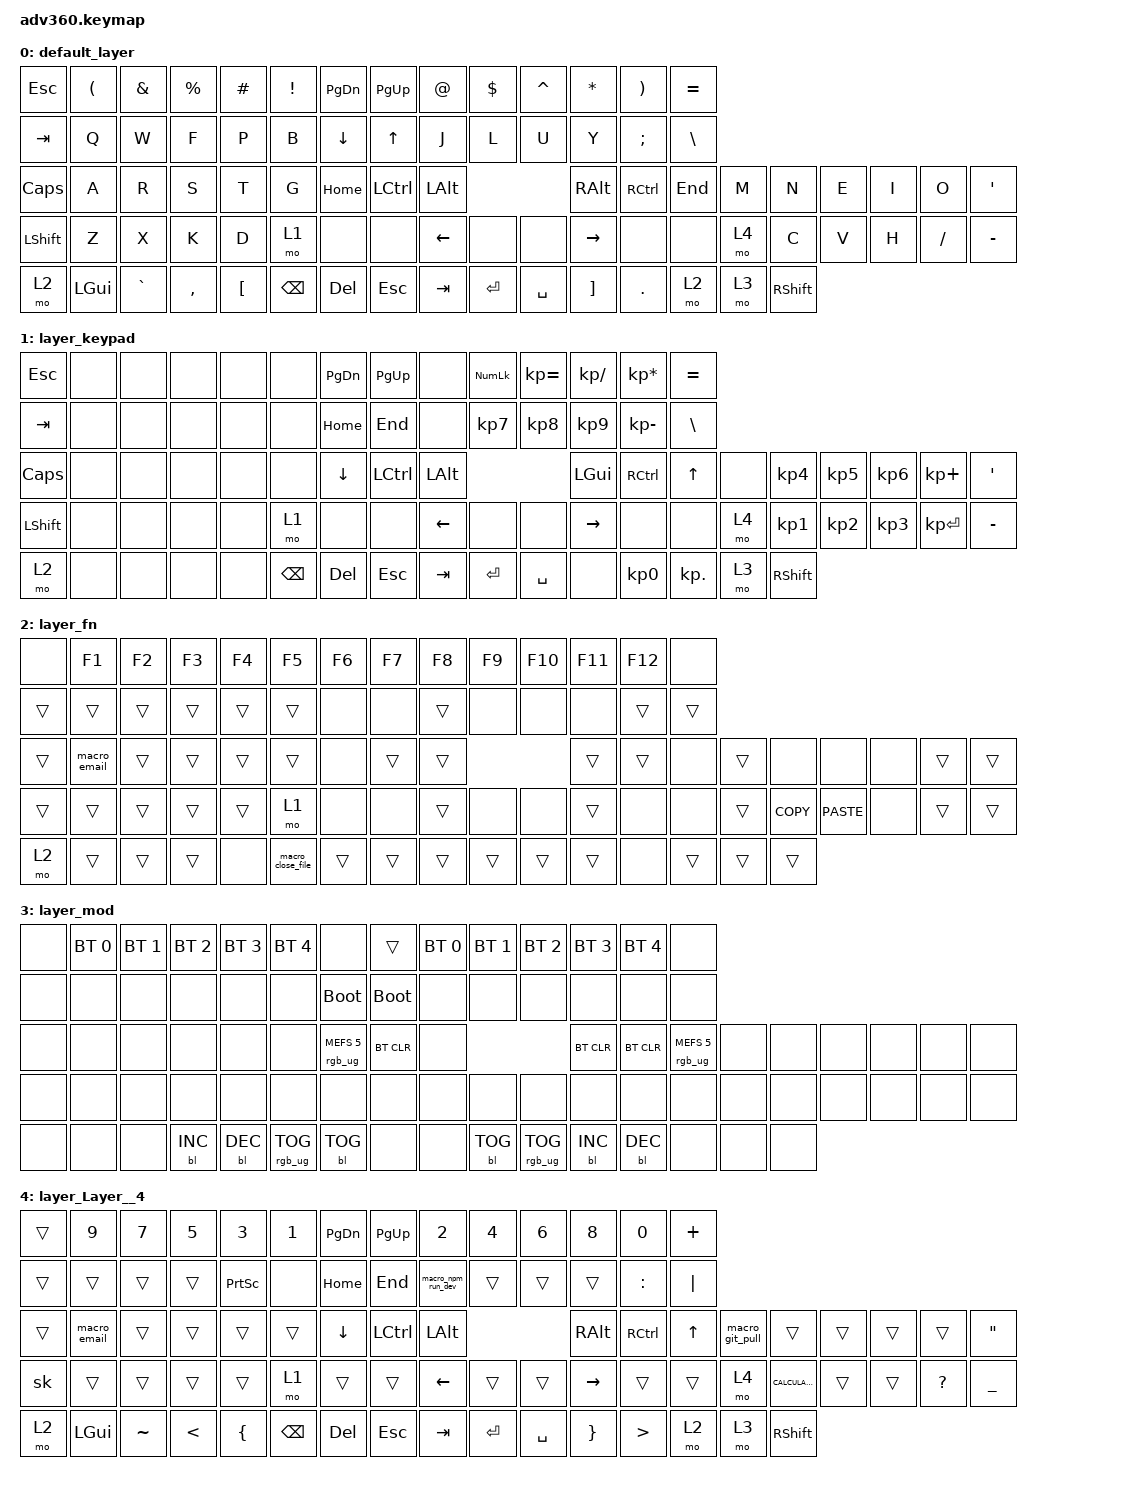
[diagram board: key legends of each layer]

/*
 * Copyright (c) 2020 The ZMK Contributors
 *
 * SPDX-License-Identifier: MIT
 */


/* THIS FILE WAS GENERATED!
 *
 * This file was generated automatically. You may or may not want to
 * edit it directly.
 */

#include <behaviors.dtsi>
#include <dt-bindings/zmk/keys.h>
#include <dt-bindings/zmk/bt.h>
#include <dt-bindings/zmk/rgb.h>
#include <dt-bindings/zmk/backlight.h>

/ {
  behaviors {
    #include "macros.dtsi"

    hm: homerow_mods {
        compatible = "zmk,behavior-hold-tap";
        label = "HOMEROW_MODS";
        #binding-cells = <2>;
        tapping-term-ms = <200>;
        quick_tap_ms = <175>;
        flavor = "tap-preferred";
        bindings = <&kp>, <&kp>;
    };
  };

    keymap {
        compatible = "zmk,keymap";


        default_layer {
            bindings = <
   &kp ESC  &kp LEFT_PARENTHESIS  &kp AMPERSAND  &kp PERCENT         &kp POUND  &kp EXCL             &kp PAGE_DOWN   &kp PAGE_UP          &kp AT  &kp DOLLAR  &kp CARET       &kp ASTERISK  &kp RIGHT_PARENTHESIS  &kp EQUAL
   &kp TAB                 &kp Q          &kp W        &kp F             &kp P     &kp B            &kp DOWN_ARROW  &kp UP_ARROW           &kp J       &kp L      &kp U              &kp Y          &kp SEMICOLON   &kp BSLH
  &kp CAPS                 &kp A          &kp R        &kp S             &kp T     &kp G                  &kp HOME     &kp LCTRL        &kp LALT                             &kp RIGHT_ALT              &kp RCTRL    &kp END   &kp M            &kp N   &kp E   &kp I     &kp O    &kp SQT
 &kp LSHFT                 &kp Z          &kp X        &kp K             &kp D     &mo 1                     &none         &none  &kp LEFT_ARROW       &none      &none    &kp RIGHT_ARROW                  &none      &none   &mo 4            &kp C   &kp V   &kp H  &kp FSLH  &kp MINUS
     &mo 2              &kp LGUI      &kp GRAVE    &kp COMMA  &kp LEFT_BRACKET  &kp BSPC                   &kp DEL       &kp ESC         &kp TAB   &kp ENTER  &kp SPACE  &kp RIGHT_BRACKET             &kp PERIOD      &mo 2   &mo 3  &kp RIGHT_SHIFT
            >;
        };

        layer_keypad {
            bindings = <
   &kp ESC   &none   &none   &none   &none     &none             &kp PAGE_DOWN  &kp PAGE_UP           &none  &kp KP_NUM  &kp KP_EQUAL    &kp KP_DIVIDE    &kp KP_MULTIPLY     &kp EQUAL
   &kp TAB   &none   &none   &none   &none     &none                  &kp HOME      &kp END           &none   &kp KP_N7     &kp KP_N8        &kp KP_N9       &kp KP_MINUS      &kp BSLH
  &kp CAPS   &none   &none   &none   &none     &none            &kp DOWN_ARROW    &kp LCTRL        &kp LALT                                   &kp LGUI  &kp RIGHT_CONTROL  &kp UP_ARROW   &none   &kp KP_N4  &kp KP_N5  &kp KP_N6   &kp KP_PLUS    &kp SQT
 &kp LSHFT   &none   &none   &none   &none     &mo 1                     &none        &none  &kp LEFT_ARROW       &none         &none  &kp RIGHT_ARROW              &none         &none   &mo 4   &kp KP_N1  &kp KP_N2  &kp KP_N3  &kp KP_ENTER  &kp MINUS
     &mo 2   &none   &none   &none   &none  &kp BSPC                   &kp DEL   &kp ESCAPE         &kp TAB   &kp ENTER     &kp SPACE            &none          &kp KP_N0    &kp KP_DOT   &mo 3  &kp RSHIFT
            >;
        };

        layer_fn {
            bindings = <
  &none        &kp F1  &kp F2  &kp F3  &kp F4             &kp F5            &kp F6  &kp F7  &kp F8  &kp F9  &kp F10  &kp F11  &kp F12   &none
 &trans        &trans  &trans  &trans  &trans             &trans             &none   &none  &trans   &none    &none    &none   &trans  &trans
 &trans  &macro_email  &trans  &trans  &trans             &trans             &none  &trans  &trans                    &trans   &trans   &none  &trans       &none        &none   &none  &trans  &trans
 &trans        &trans  &trans  &trans  &trans              &mo 1             &none   &none  &trans   &none    &none   &trans    &none   &none  &trans  &kp K_COPY  &kp K_PASTE   &none  &trans  &trans
  &mo 2        &trans  &trans  &trans   &none  &macro_close_file            &trans  &trans  &trans  &trans   &trans   &trans    &none  &trans  &trans      &trans
            >;
        };

        layer_mod {
            bindings = <
  &none  &bt BT_SEL 0  &bt BT_SEL 1  &bt BT_SEL 2  &bt BT_SEL 3     &bt BT_SEL 4                             &none       &trans  &bt BT_SEL 0  &bt BT_SEL 1     &bt BT_SEL 2  &bt BT_SEL 3  &bt BT_SEL 4                   &none
  &none         &none         &none         &none         &none            &none                       &bootloader  &bootloader         &none         &none            &none         &none         &none                   &none
  &none         &none         &none         &none         &none            &none            &rgb_ug RGB_MEFS_CMD 5   &bt BT_CLR         &none                                   &bt BT_CLR    &bt BT_CLR  &rgb_ug RGB_MEFS_CMD 5   &none   &none   &none   &none   &none   &none
  &none         &none         &none         &none         &none            &none                             &none        &none         &none         &none            &none         &none         &none                   &none   &none   &none   &none   &none   &none   &none
  &none         &none         &none    &bl BL_INC    &bl BL_DEC  &rgb_ug RGB_TOG                        &bl BL_TOG        &none         &none    &bl BL_TOG  &rgb_ug RGB_TOG    &bl BL_INC    &bl BL_DEC                   &none   &none   &none
            >;
        };

        layer_Layer__4 {
            bindings = <
 &trans        &kp N9     &kp N7         &kp N5           &kp N3         &kp N1             &kp PAGE_DOWN  &kp PG_UP              &kp N2     &kp N4     &kp N6           &kp N8            &kp N0      &kp PLUS
 &trans        &trans     &trans         &trans  &kp PRINTSCREEN          &none                  &kp HOME    &kp END  &macro_npm_run_dev     &trans     &trans           &trans         &kp COLON      &kp PIPE
 &trans  &macro_email     &trans         &trans           &trans         &trans            &kp DOWN_ARROW  &kp LCTRL        &kp LEFT_ALT                          &kp RIGHT_ALT         &kp RCTRL  &kp UP_ARROW  &macro_git_pull            &trans  &trans  &trans        &trans  &kp DOUBLE_QUOTES
    &sk        &trans     &trans         &trans           &trans          &mo 1                    &trans     &trans      &kp LEFT_ARROW     &trans     &trans  &kp RIGHT_ARROW            &trans        &trans            &mo 4  &kp K_CALCULATOR  &trans  &trans  &kp QUESTION     &kp UNDERSCORE
  &mo 2      &kp LGUI  &kp TILDE  &kp LESS_THAN   &kp LEFT_BRACE  &kp BACKSPACE                &kp DELETE    &kp ESC             &kp TAB  &kp ENTER  &kp SPACE  &kp RIGHT_BRACE  &kp GREATER_THAN         &mo 2            &mo 3   &kp RIGHT_SHIFT
            >;
        };

    };
};
